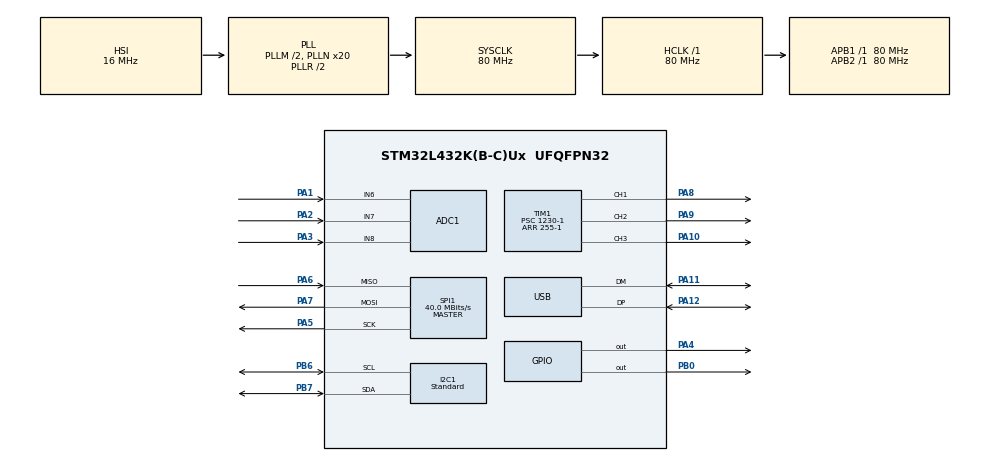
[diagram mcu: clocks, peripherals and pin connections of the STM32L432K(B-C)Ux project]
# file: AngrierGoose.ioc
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ADC1.Channel-0\#ChannelRegularConversion=ADC_CHANNEL_6
ADC1.NbrOfConversionFlag=1
ADC1.OffsetNumber-0\#ChannelRegularConversion=ADC_OFFSET_NONE
ADC1.Rank-0\#ChannelRegularConversion=1
ADC1.SamplingTime-0\#ChannelRegularConversion=ADC_SAMPLETIME_2CYCLES_5
ADC1.master=1
I2C1.I2C_Speed_Mode=I2C_Standard
I2C1.Timing=0x10909CEC
Mcu.Family=STM32L4
Mcu.Name=STM32L432K(B-C)Ux
Mcu.Package=UFQFPN32
NVIC.PriorityGroup=NVIC_PRIORITYGROUP_4
NVIC.USB_IRQn=true\:0\:0\:false\:false\:true\:false\:true
PA0.Mode=HSE-External-Clock-Source-for-LittleOrca
PA0.Signal=RCC_CK_IN
PA1.Signal=ADCx_IN6
PA10.Signal=S_TIM1_CH3
PA11.Mode=Device
PA11.Signal=USB_DM
PA12.Mode=Device
PA12.Signal=USB_DP
PA13\ (JTMS-SWDIO).Mode=Serial_Wire
PA13\ (JTMS-SWDIO).Signal=SYS_JTMS-SWDIO
PA14\ (JTCK-SWCLK).Mode=Serial_Wire
PA14\ (JTCK-SWCLK).Signal=SYS_JTCK-SWCLK
PA2.Signal=ADCx_IN7
PA3.Signal=ADCx_IN8
PA4.Signal=GPIO_Output
PA5.Mode=Full_Duplex_Master
PA5.Signal=SPI1_SCK
PA6.Mode=Full_Duplex_Master
PA6.Signal=SPI1_MISO
PA7.Mode=Full_Duplex_Master
PA7.Signal=SPI1_MOSI
PA8.Signal=S_TIM1_CH1
PA9.Signal=S_TIM1_CH2
PB0.Signal=GPIO_Output
PB6.GPIO_Pu=GPIO_PULLUP
PB6.Mode=I2C
PB6.Signal=I2C1_SCL
PB7.GPIO_Pu=GPIO_PULLUP
PB7.Mode=I2C
PB7.Signal=I2C1_SDA
PC14-OSC32_IN\ (PC14).Mode=LSE-External-Oscillator
PC14-OSC32_IN\ (PC14).Signal=RCC_OSC32_IN
PC15-OSC32_OUT\ (PC15).Mode=LSE-External-Oscillator
PC15-OSC32_OUT\ (PC15).Signal=RCC_OSC32_OUT
ProjectManager.HeapSize=0x200
ProjectManager.StackSize=0x400
ProjectManager.TargetToolchain=STM32CubeIDE
RCC.ADCFreq_Value=10666666.666666666
RCC.AHBFreq_Value=80000000
RCC.APB1Freq_Value=80000000
RCC.APB1TimFreq_Value=80000000
RCC.APB2Freq_Value=80000000
RCC.APB2TimFreq_Value=80000000
RCC.CK48CLockSelection=RCC_USBCLKSOURCE_HSI48
RCC.CortexFreq_Value=80000000
RCC.HCLKFreq_Value=80000000
RCC.HSE_VALUE=0
RCC.HSI48_VALUE=48000000
RCC.HSI_VALUE=16000000
RCC.I2C1CLockSelection=RCC_I2C1CLKSOURCE_SYSCLK
RCC.MSIClockRange=RCC_MSIRANGE_11
RCC.MSI_VALUE=48000000
RCC.PLLM=2
RCC.PLLN=20
RCC.PLLSAI1R=RCC_PLLR_DIV6
RCC.PLLSourceVirtual=RCC_PLLSOURCE_HSI
RCC.SYSCLKFreq_VALUE=80000000
RCC.SYSCLKSource=RCC_SYSCLKSOURCE_PLLCLK
RCC.USBFreq_Value=48000000
RCC.VCOOutputFreq_Value=160000000
SH.ADCx_IN6.0=ADC1_IN6,IN6-Single-Ended
SH.ADCx_IN7.0=ADC1_IN7,IN7-Single-Ended
SH.ADCx_IN8.0=ADC1_IN8,IN8-Single-Ended
SH.S_TIM1_CH1.0=TIM1_CH1,PWM Generation1 CH1
SH.S_TIM1_CH2.0=TIM1_CH2,PWM Generation2 CH2
SH.S_TIM1_CH3.0=TIM1_CH3,PWM Generation3 CH3
SPI1.BaudRatePrescaler=SPI_BAUDRATEPRESCALER_2
SPI1.CalculateBaudRate=40.0 MBits/s
SPI1.DataSize=SPI_DATASIZE_8BIT
SPI1.Direction=SPI_DIRECTION_2LINES
SPI1.Mode=SPI_MODE_MASTER
SPI1.VirtualType=VM_MASTER
TIM1.Channel-PWM\ Generation1\ CH1=TIM_CHANNEL_1
TIM1.Channel-PWM\ Generation2\ CH2=TIM_CHANNEL_2
TIM1.Channel-PWM\ Generation3\ CH3=TIM_CHANNEL_3
TIM1.Period=255-1
TIM1.Prescaler=1230-1
USB_DEVICE.CLASS_NAME_FS=CDC
USB_DEVICE.VirtualMode=Cdc
USB_DEVICE.VirtualModeFS=Cdc_FS
VP_USB_DEVICE_VS_USB_DEVICE_CDC_FS.Mode=CDC_FS
board=custom

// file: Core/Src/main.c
/* USER CODE BEGIN Header */
/**
  ******************************************************************************
  * @file           : main.c
  * @brief          : Main program body
  ******************************************************************************
  * @attention
  *
  * <h2><center>&copy; Copyright (c) 2021 STMicroelectronics.
  * All rights reserved.</center></h2>
  *
  * This software component is licensed by ST under Ultimate Liberty license
  * SLA0044, the "License"; You may not use this file except in compliance with
  * the License. You may obtain a copy of the License at:
  *                             www.st.com/SLA0044
  *
  ******************************************************************************
  */
/* USER CODE END Header */
#include "main.h"
#include "adc.h"
#include "i2c.h"
#include "spi.h"
#include "tim.h"
#include "usb_device.h"
#include "gpio.h"

/* USER CODE BEGIN Includes */
#include "usbd_cdc_if.h"
#include "../../Devices/S25FLx.h"

#define ARM_MATH_CM4
#include "arm_math.h"

/* USER CODE END Includes */

void SystemClock_Config(void);

int main(void)
{

  /* MCU Configuration--------------------------------------------------------*/

  /* Reset of all peripherals, Initializes the Flash interface and the Systick. */
  HAL_Init();

  /* Configure the system clock */
  SystemClock_Config();

  /* Initialize all configured peripherals */
  MX_GPIO_Init();
  MX_ADC1_Init();
  MX_I2C1_Init();
  MX_SPI1_Init();
  MX_TIM1_Init();
  MX_USB_DEVICE_Init();
  /* USER CODE BEGIN 2 */
  HAL_TIM_PWM_Start(&htim1, TIM_CHANNEL_3);
uint8_t value = 0;
  /* USER CODE END 2 */

  /* Infinite loop */
  /* USER CODE BEGIN WHILE */
  while (1)
  {
//
//	  HAL_GPIO_TogglePin(GPIOA, GPIO_PIN_4);
//	  uint8_t b[] = "hello\r\n";
//	  CDC_Transmit_FS(b, strlen(b));

	  HAL_GPIO_TogglePin(GPIOA, GPIO_PIN_4);
	  /*while (value < 255) {
		  htim1.Instance->CCR3 = value;
		  value += 20;
		  HAL_Delay (500);
	  }*/
	  HAL_Delay(1000);

	/*
	for(uint8_t addr = 0; addr < 128; addr++) {
		uint8_t exists = HAL_I2C_IsDeviceReady(&hi2c1, addr << 1, 10, 50) == HAL_OK;
		if(exists) {
			sprintf(output, "0x%X", addr);
		} else {
			sprintf(output, ".");
		}
		CDC_Transmit_FS((uint8_t*)output, (uint16_t)strlen(output));
	}

	//uint8_t has_baro = HAL_I2C_IsDeviceReady(&hi2c1, baro_addr, 10, 100) == HAL_OK;
	sprintf(output, "done\n");
	CDC_Transmit_FS((uint8_t*)output, strlen(output));
	HAL_Delay(1000);
*/
    /* USER CODE END WHILE */

  }
}

void SystemClock_Config(void)
{
  RCC_OscInitTypeDef RCC_OscInitStruct = {0};
  RCC_ClkInitTypeDef RCC_ClkInitStruct = {0};

  /** Configure the main internal regulator output voltage
  */
  if (HAL_PWREx_ControlVoltageScaling(PWR_REGULATOR_VOLTAGE_SCALE1) != HAL_OK)
  {
    Error_Handler();
  }
  /** Initializes the RCC Oscillators according to the specified parameters
  * in the RCC_OscInitTypeDef structure.
  */
  RCC_OscInitStruct.OscillatorType = RCC_OSCILLATORTYPE_HSI48|RCC_OSCILLATORTYPE_HSI;
  RCC_OscInitStruct.HSIState = RCC_HSI_ON;
  RCC_OscInitStruct.HSI48State = RCC_HSI48_ON;
  RCC_OscInitStruct.HSICalibrationValue = RCC_HSICALIBRATION_DEFAULT;
  RCC_OscInitStruct.PLL.PLLState = RCC_PLL_ON;
  RCC_OscInitStruct.PLL.PLLSource = RCC_PLLSOURCE_HSI;
  RCC_OscInitStruct.PLL.PLLM = 2;
  RCC_OscInitStruct.PLL.PLLN = 20;
  RCC_OscInitStruct.PLL.PLLP = RCC_PLLP_DIV7;
  RCC_OscInitStruct.PLL.PLLQ = RCC_PLLQ_DIV2;
  RCC_OscInitStruct.PLL.PLLR = RCC_PLLR_DIV2;
  if (HAL_RCC_OscConfig(&RCC_OscInitStruct) != HAL_OK)
  {
    Error_Handler();
  }
  /** Initializes the CPU, AHB and APB buses clocks
  */
  RCC_ClkInitStruct.ClockType = RCC_CLOCKTYPE_HCLK|RCC_CLOCKTYPE_SYSCLK
                              |RCC_CLOCKTYPE_PCLK1|RCC_CLOCKTYPE_PCLK2;
  RCC_ClkInitStruct.SYSCLKSource = RCC_SYSCLKSOURCE_PLLCLK;
  RCC_ClkInitStruct.AHBCLKDivider = RCC_SYSCLK_DIV1;
  RCC_ClkInitStruct.APB1CLKDivider = RCC_HCLK_DIV1;
  RCC_ClkInitStruct.APB2CLKDivider = RCC_HCLK_DIV1;

  if (HAL_RCC_ClockConfig(&RCC_ClkInitStruct, FLASH_LATENCY_4) != HAL_OK)
  {
    Error_Handler();
  }
}

void Error_Handler(void)
{
}
